# CH32V203G6U6 register map
Vendor: WCH; File version: 0.1.0
CPU: QingKe V4B V4B, little endian, no MPU, no FPU, vendor SysTick, 4 interrupt priority bits
Registers are 16-bit, read-write, reset 0x0 unless marked. A register's access mark holds for its fields unless they carry their own. Offsets are from the block's base; [hi:lo] are bit positions; {n}, {i} and the like mark numbered series.

## TIM2 — General-purpose timer 2
Base 0x40000000
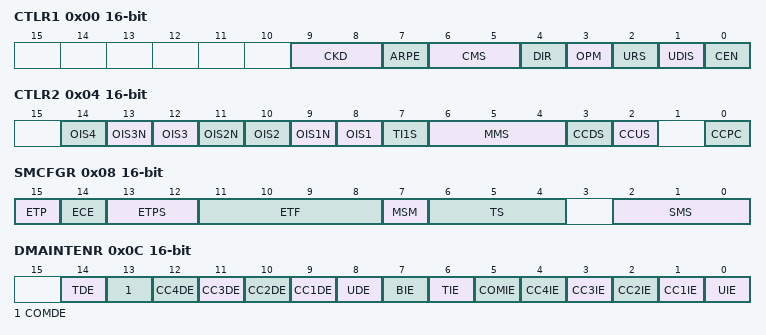
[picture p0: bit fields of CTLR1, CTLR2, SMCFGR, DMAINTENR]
0x00 CTLR1 — control register 1
  [9:8] CKD — Clock division
  [7] ARPE — Auto-reload preload enable
  [6:5] CMS — Center-aligned mode selection
  [4] DIR — Direction
  [3] OPM — One-pulse mode
  [2] URS — Update request source
  [1] UDIS — Update disable
  [0] CEN — Counter enable
0x04 CTLR2 — control register 2
  [2n+6] OIS{n} (n=1..4)
  [13] OIS3N
  [11] OIS2N
  [9] OIS1N
  [7] TI1S — TI1 selection
  [6:4] MMS — Master mode selection
  [3] CCDS — Capture/compare DMA selection
  [2] CCUS — Update selection
  [0] CCPC — Compare selection
0x08 SMCFGR — slave mode control register
  [15] ETP — External trigger polarity
  [14] ECE — External clock enable
  [13:12] ETPS — External trigger prescaler
  [11:8] ETF — External trigger filter
  [7] MSM — Master/Slave mode
  [6:4] TS — Trigger selection
  [2:0] SMS — Slave mode selection
0x0C DMAINTENR — DMA/Interrupt enable register
  [14] TDE — Trigger DMA request enable
  [13] COMDE — COM DMA request enable
  [n+8] CC{n}DE (n=1..4) — Capture/Compare {n} DMA request enable
  [8] UDE — Update DMA request enable
  [7] BIE
  [6] TIE — Trigger interrupt enable
  [5] COMIE
  [n] CC{n}IE (n=1..4) — Capture/Compare {n} interrupt enable
  [0] UIE — Update interrupt enable
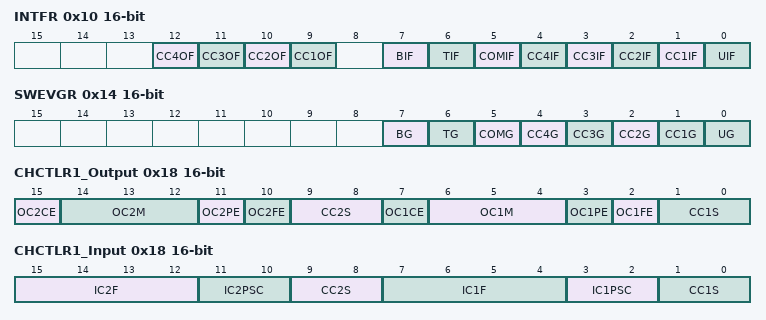
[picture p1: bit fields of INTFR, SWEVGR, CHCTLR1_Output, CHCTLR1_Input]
0x10 INTFR — status register
  [12] CC4OF — Capture/Compare 4 overcapture flag
  [11] CC3OF — Capture/Compare 3 overcapture flag
  [10] CC2OF — Capture/compare 2 overcapture flag
  [9] CC1OF — Capture/Compare 1 overcapture flag
  [7] BIF
  [6] TIF — Trigger interrupt flag
  [5] COMIF
  [4] CC4IF — Capture/Compare 4 interrupt flag
  [3] CC3IF — Capture/Compare 3 interrupt flag
  [2] CC2IF — Capture/Compare 2 interrupt flag
  [1] CC1IF — Capture/compare 1 interrupt flag
  [0] UIF — Update interrupt flag
0x14 SWEVGR — event generation register
  [7] BG — Brake generation
  [6] TG — Trigger generation
  [5] COMG — Capture/compare generation
  [n] CC{n}G (n=1..4) — Capture/compare {n} generation
  [0] UG — Update generation
0x18 CHCTLR1_Output reset not defined — capture/compare mode register 1 (output mode)
  [15] OC2CE — Output compare 2 clear enable
  [14:12] OC2M — Output compare 2 mode
  [11] OC2PE — Output compare 2 preload enable
  [10] OC2FE — Output compare 2 fast enable
  [9:8] CC2S — Capture/Compare 2 selection
  [7] OC1CE — Output compare 1 clear enable
  [6:4] OC1M — Output compare 1 mode
  [3] OC1PE — Output compare 1 preload enable
  [2] OC1FE — Output compare 1 fast enable
  [1:0] CC1S — Capture/Compare 1 selection
0x18 CHCTLR1_Input reset not defined (alternate view of CHCTLR1_Output) — capture/compare mode register 1 (input mode)
  [15:12] IC2F — Input capture 2 filter
  [11:10] IC2PSC — Input capture 2 prescaler
  [9:8] CC2S — Capture/Compare 2 selection
  [7:4] IC1F — Input capture 1 filter
  [3:2] IC1PSC — Input capture 1 prescaler
  [1:0] CC1S — Capture/Compare 1 selection
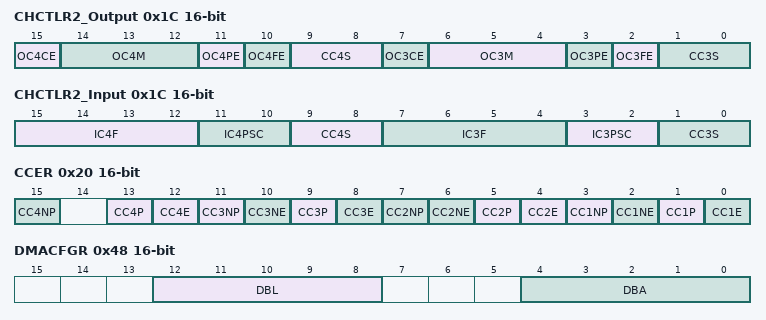
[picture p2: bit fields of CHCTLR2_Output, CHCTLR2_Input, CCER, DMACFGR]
0x1C CHCTLR2_Output reset not defined — capture/compare mode register 2 (output mode)
  [15] OC4CE — Output compare 4 clear enable
  [14:12] OC4M — Output compare 4 mode
  [11] OC4PE — Output compare 4 preload enable
  [10] OC4FE — Output compare 4 fast enable
  [9:8] CC4S — Capture/Compare 4 selection
  [7] OC3CE — Output compare 3 clear enable
  [6:4] OC3M — Output compare 3 mode
  [3] OC3PE — Output compare 3 preload enable
  [2] OC3FE — Output compare 3 fast enable
  [1:0] CC3S — Capture/Compare 3 selection
0x1C CHCTLR2_Input reset not defined (alternate view of CHCTLR2_Output) — capture/compare mode register 2 (input mode)
  [15:12] IC4F — Input capture 4 filter
  [11:10] IC4PSC — Input capture 4 prescaler
  [9:8] CC4S — Capture/Compare 4 selection
  [7:4] IC3F — Input capture 3 filter
  [3:2] IC3PSC — Input capture 3 prescaler
  [1:0] CC3S — Capture/Compare 3 selection
0x20 CCER — capture/compare enable register
  [4n-1] CC{n}NP (n=1..4)
  [13] CC4P — Capture/Compare 3 output Polarity
  [4n-4] CC{n}E (n=1..4) — Capture/Compare {n} output enable
  [10] CC3NE
  [9] CC3P — Capture/Compare 3 output Polarity
  [6] CC2NE
  [5] CC2P — Capture/Compare 2 output Polarity
  [2] CC1NE
  [1] CC1P — Capture/Compare 1 output Polarity
0x24 CNT 32-bit — counter
0x28 PSC — prescaler
  [15:0] PSC — Prescaler value
0x2C ATRLR 32-bit — auto-reload register
{0x30+4i} CH{i}CVR 32-bit (i=1..4) — capture/compare register {i}
0x48 DMACFGR — DMA control register
  [12:8] DBL — DMA burst length
  [4:0] DBA — DMA base address
0x4C DMAADR — DMA address for full transfer
  [15:0] DMAR_DMAB

## TIM3 — General-purpose timer 3
Base 0x40000400
Same registers: TIM4 0x40000800
Registers as TIM2; these are added or differ:
0x24 CNT — counter
  [15:0] CNT — counter value
0x2C ATRLR — auto-reload register
  [15:0] ARR
{0x30+4i} CH{i}CVR (i=1..4) — capture/compare register {i}
  [15:0] CCR{i}
